# AE402FA0E5597LE0_CM55_HP_View register map
Vendor: Alif Semiconductor; Series: E4; File version: 1.0
CPU: CM55 r1p0, selectable endian, MPU, FPU, double-precision FPU, DSP, VTOR, 8 interrupt priority bits, 1 SAU regions
Registers are 32-bit, read-write, reset 0x0 unless marked. A register's access mark holds for its fields unless they carry their own. Offsets are from the block's base; [hi:lo] are bit positions; lines under a group give offsets from that group; {n}, {i} and the like mark numbered series; 'fields as' and 'values as' point back to an identical list.

## LPTIMER
Base 0x42001000
{0x0+0x14*i} LPTIMER_CHANNEL_CFG[{i}] (i=0..3) group
  0x00 LPTIMER_LOADCOUNT — Timer (n) Load Count Register
    [31:0] TIMERN_LOADCOUNT — Value to be loaded into Timer (n). This is the value from which counting commences. Any value written to this register is loaded into the associated timer.
  0x04 LPTIMER_CURRENTVAL ro reset 0x80000000 — Timer (n) Current Value Register
    [31:0] TIMERN_CURRENTVALUE — Current Value of Timer (n)
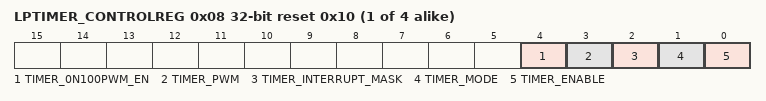
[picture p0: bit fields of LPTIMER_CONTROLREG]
  0x08 LPTIMER_CONTROLREG reset 0x10 — Timer (n) Control Register
    [4] TIMER_0N100PWM_EN ro — 0% and 100% PWM duty cycle mode for Timer (n). Hardcoded to enabled state to reduce software overhead.
      1=Enabled
    [3] TIMER_PWM — Pulse Width Modulation of Timer (n) toggle output.
      0=PWM is disabled (normal toggle); 1=PWM is enabled (PWM toggle)
    [2] TIMER_INTERRUPT_MASK — Timer interrupt mask for Timer (n).
      0=Timer (n) interrupt is unmasked; 1=Timer (n) interrupt is masked
    [1] TIMER_MODE — Timer mode for Timer (n). Note: All bits of the LPTIMERn_LOADCOUNT register must be set to 1 before enabling Timer (n) in free-running mode.
      0=Free-running count; 1=User-defined count
    [0] TIMER_ENABLE — Timer enable bit for Timer (n).
      0=Timer (n) is disabled; 1=Timer (n) is enabled
  0x0C LPTIMER_EOI ro — Timer (n) End-of-Interrupt Register
    [0] TIMERN_EOI — End-of-Interrupt for Timer (n).
  0x10 LPTIMER_INTSTAT ro — Timer (n) Interrupt Status Register
    [0] TIMERN_INTSTATUS — Interrupt status for Timer (n) after mask:
      0=Timer (n) interrupt is inactive. IRQ line is not asserted.; 1=Timer (n) interrupt is active. IRQ line is asserted.
0xA0 LPTIMERS_INTSTATUS ro — Timers Interrupt Status Register
  [3:0] TIMERS_INTSTATUS — Interrupt status of all timers after mask, where: Bit 3: LPTIMER3 Bit 2: LPTIMER2 Bit 1: LPTIMER1 Bit 0: LPTIMER0 For each bit:
    values as LPTIMER_CHANNEL_CFG[0].LPTIMER_INTSTAT.TIMERN_INTSTATUS
0xA4 LPTIMERS_EOI ro — Timers End-of-Interrupt Register
  [3:0] TIMERS_EOI — End-of-Interrupt for all timers, where: Bit 3: LPTIMER3 Bit 2: LPTIMER2 Bit 1: LPTIMER1 Bit 0: LPTIMER0
0xA8 LPTIMERS_RAWINTSTATUS ro — Timers Raw Interrupt Status Register
  [3:0] TIMERS_RAWINTSTAT — Raw interrupt status of all timers, where: Bit 3: LPTIMER3 Bit 2: LPTIMER2 Bit 1: LPTIMER1 Bit 0: LPTIMER0 For each bit:
    0=Raw Timer (n) interrupt is inactive; 1=Raw Timer (n) interrupt is active
0xAC LPTIMERS_COMP_VERSION ro reset 0x3231322A — LPTIMER Component Version
  [31:0] TIMERS_COMP_VERSION — LPTIMER version number
{0xB0+4i} LPTIMER_LOADCOUNT2[{i}] (i=0..3) — Timer (n) Load Count2 Register
  [31:0] TIMERN_LOADCOUNT2 — Value to be loaded into Timer (n) when toggle output changes from 0 to 1. This value determines the width of the high period of the toggle output.

## LPCMP
Base 0x42003000
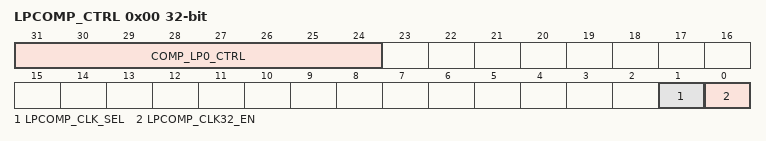
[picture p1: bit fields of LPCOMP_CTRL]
0x00 LPCOMP_CTRL — LPCMP Control Register
  [31:24] COMP_LP0_CTRL — LPCMP Control Register Bits [31-29]: Set LPCMP hysteresis level in 6-mV steps 0x0: 0 mV ... 0x7: 45 mV Bits [28-27]: Select input to negative terminal of LPCMP 0x0: Internal AON Vref (0.8 V) 0x1: VREF_IN0 pin 0x2: VREF_IN1 pin 0x3: VREF_IN2 pin Bits [26-25]: Select input to positive terminal of LPCMP 0x0: LPCMP_IN0 pin 0x1: LPCMP_IN1 pin 0x2: LPCMP_IN2 pin 0x3: LPCMP_IN3 pin Bit [24]: LPCMP Enable 0x0: Disable 0x1: Enable
  [1] LPCOMP_CLK_SEL — LPCMP Clock Source Selection
    0=32-kHz XTAL oscillator (LFXO); 1=32-kHz RC oscillator (LFRC)
  [0] LPCOMP_CLK32_EN — LPCMP 32-kHz Clock Enable
    0=Disable; 1=Enable

## BOR_BOD
Base 0x42004000
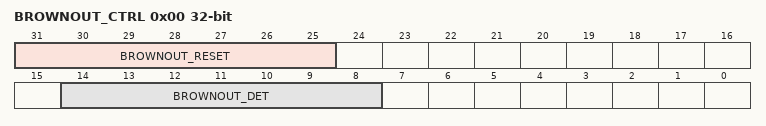
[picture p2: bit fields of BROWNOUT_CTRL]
0x00 BROWNOUT_CTRL — BOR and BOD Control Register
  [31:25] BROWNOUT_RESET — Brownout Reset (BOR) control Bits [31:29]: Control for BOR threshold level 000: 1.53 mV 111: 1.802 mV Step: 24 mV Bits [28:26]: Control for BOR hysteresis 000: 0 mV 111: 160 mV Step: 23 mV Bit [25]: Enables BOR circuit (0 = Disable, 1 = Enable)
  [14:8] BROWNOUT_DET — Brownout Detect (BOD) control Bits [14:12]: Control for BOD threshold level 000: 1.634 V 111: 1.802 V Step: 24 mV Bits [11:9]: Control for BOD hysteresis 000: 0 mV 111: 160 mV Step: 23 mV Bit [8]: Enables BOD circuit (0 = Disable, 1 = Enable)
